# MSP430FR5962 register map
File version: 2.1
CPU: MSP430FR5962 r2p1, little endian, MPU, no FPU, 3 interrupt priority bits
Registers are 16-bit, read-write, reset 0x0 unless marked. A register's access mark holds for its fields unless they carry their own. Offsets are from the block's base; [hi:lo] are bit positions; lines under a group give offsets from that group; {n}, {i} and the like mark numbered series.

## TB0
Base 0x000003C0
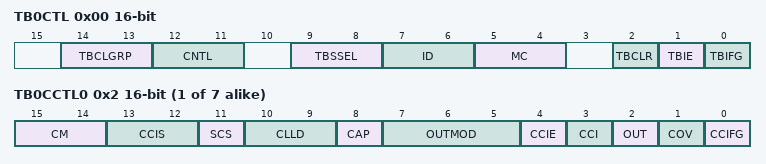
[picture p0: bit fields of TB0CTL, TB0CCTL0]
0x00 TB0CTL — Timer_B Control Register
  [14:13] TBCLGRP — [14:13] TBxCLn group
    0=Each TBxCLn latch loads independently; 1=TBxCL1+TBxCL2 (TBxCCR1 CLLD bits control the update); TBxCL3+TBxCL4 (TBxCCR3 CLLD bits control the update); TBxCL5+TBxCL6 (TBxCCR5 CLLD bits control the update); TBxCL0 independent; 2=TBxCL1+TBxCL2+TBxCL3 (TBxCCR1 CLLD bits control the update); TBxCL4+TBxCL5+TBxCL6 (TBxCCR4 CLLD bits control the update); TBxCL0 independent; 3=TBxCL0+TBxCL1+TBxCL2+TBxCL3+TBxCL4+TBxCL5+TBxCL6 (TBxCCR1 CLLD bits control the update)
  [12:11] CNTL — [12:11] Counter length
    0=16-bit, TBxR(max) = 0FFFFh; 1=12-bit, TBxR(max) = 0FFFh; 2=10-bit, TBxR(max) = 03FFh; 3=8-bit, TBxR(max) = 0FFh
  [9:8] TBSSEL — [9:8] TimerB clock source select
    0=TBCLK (TBxCLK); 1=ACLK; 2=SMCLK; 3=INCLK
  [7:6] ID — [7:6] Input divider
    0=1; 1=2; 2=4; 3=8
  [5:4] MC — [5:4] Mode control
    0=STOP (Stop mode: Timer is halted); 1=UP (Up mode: Timer counts up to TBxCL0); 2=CONTINUOUS (Continuous mode: Timer counts up to the value set by CNTL); 3=UPDOWN (Up/down mode: Timer counts up to TBxCL0 then down to 0000h)
  [2] TBCLR — [2:2] TimerB clear
  [1] TBIE — [1:1] TimerB interrupt enable
    0=Interrupt disabled; 1=Interrupt enabled
  [0] TBIFG — [0:0] TimerB interrupt flag
    0=No interrupt pending; 1=Interrupt pending
{0x2+2i} TB0CCTL{i} (i=0..6) — Timer_B Capture/Compare Control Register
  [15:14] CM — [15:14] Capture mode
    0=NONE (No capture); 1=RISING (Capture on rising edge); 2=FALLING (Capture on falling edge); 3=BOTH (Capture on both rising and falling edges)
  [13:12] CCIS — [13:12] Capture/compare input select
    0=CCIA (CCIxA); 1=CCIB (CCIxB); 2=GND; 3=VCC
  [11] SCS — [11:11] Synchronize capture source
    0=ASYNC (Asynchronous capture); 1=SYNC (Synchronous capture)
  [10:9] CLLD — [10:9] Compare latch load
    0=TBxCLn loads on write to TBxCCRn; 1=TBxCLn loads when TBxR counts to 0; 2=TBxCLn loads when TBxR counts to 0 (up or continuous mode). TBxCLn loads when TBxR counts to TBxCL0 or to 0 (up/down mode).; 3=TBxCLn loads when TBxR counts to TBxCLn
  [8] CAP — [8:8] Capture mode
    0=COMPARE (Compare mode); 1=CAPTURE (Capture mode)
  [7:5] OUTMOD — [7:5] Output mode
    0=OUT bit value; 1=Set; 2=Toggle/reset; 3=Set/reset; 4=Toggle; 5=Reset; 6=Toggle/set; 7=Reset/set
  [4] CCIE — [4:4] Capture/compare interrupt enable
    0=Interrupt disabled; 1=Interrupt enabled
  [3] CCI — [3:3] Capture/compare input
  [2] OUT — [2:2] Output
    0=LOW (Output low); 1=HIGH (Output high)
  [1] COV — [1:1] Capture overflow
    0=No capture overflow occurred; 1=Capture overflow occurred
  [0] CCIFG — [0:0] Capture/compare interrupt flag
    0=No interrupt pending; 1=Interrupt pending
0x10 TB0R — Timer_B count register
{0x12+2i} TB0CCR{i} (i=0..6) — Timer_B Capture/Compare Register
0x20 TB0EX0 — Timer_Bx Expansion Register 0
  [2:0] TBIDEX — [2:0] Input divider expansion
    {v}=Divide by {v+1} (v=0..7)
0x2E TB0IV — Timer_Bx Interrupt Vector Register
  [15:0] TBIV — [15:0] Timer_B interrupt vector value
    0=NONE (No interrupt pending); 2=TBCCR1 (Interrupt Source: Capture/compare 1; Interrupt Flag: TBxCCR1 CCIFG; Interrupt Priority: Highest); 4=TBCCR2 (Interrupt Source: Capture/compare 2; Interrupt Flag: TBxCCR2 CCIFG); 6=TBCCR3 (Interrupt Source: Capture/compare 3; Interrupt Flag: TBxCCR3 CCIFG); 8=TBCCR4 (Interrupt Source: Capture/compare 4; Interrupt Flag: TBxCCR4 CCIFG); 10=TBCCR5 (Interrupt Source: Capture/compare 5; Interrupt Flag: TBxCCR5 CCIFG); 12=TBCCR6 (Interrupt Source: Capture/compare 6; Interrupt Flag: TBxCCR6 CCIFG); 14=TBIFG (Interrupt Source: Timer overflow; Interrupt Flag: TBxCTL TBIFG; Interrupt Priority: Lowest)
